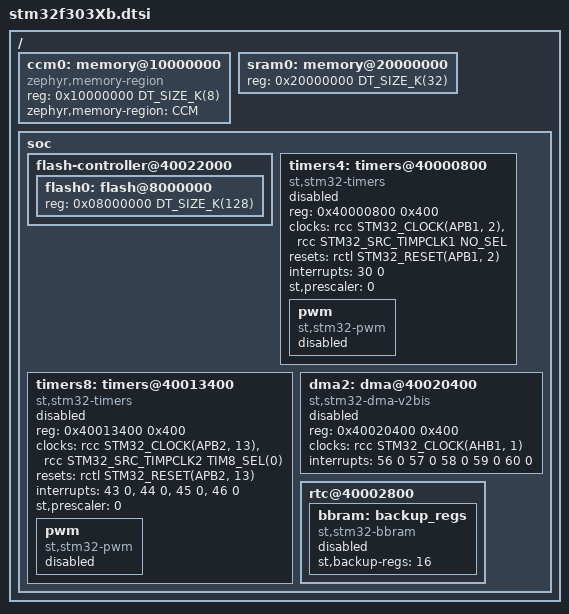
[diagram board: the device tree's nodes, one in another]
/*
 * Copyright (c) 2023 Martin Gritzan
 *
 * SPDX-License-Identifier: Apache-2.0
 */

#include <mem.h>
#include <st/f3/stm32f303.dtsi>

/ {
	ccm0: memory@10000000 {
		compatible = "zephyr,memory-region", "st,stm32-ccm";
		reg = <0x10000000 DT_SIZE_K(8)>;
		zephyr,memory-region = "CCM";
	};

	sram0: memory@20000000 {
		reg = <0x20000000 DT_SIZE_K(32)>;
	};

	soc {
		flash-controller@40022000 {
			flash0: flash@8000000 {
				reg = <0x08000000 DT_SIZE_K(128)>;
			};
		};

		timers4: timers@40000800 {
			compatible = "st,stm32-timers";
			reg = <0x40000800 0x400>;
			clocks = <&rcc STM32_CLOCK(APB1, 2)>,
				 <&rcc STM32_SRC_TIMPCLK1 NO_SEL>;
			resets = <&rctl STM32_RESET(APB1, 2)>;
			interrupts = <30 0>;
			interrupt-names = "global";
			st,prescaler = <0>;
			status = "disabled";

			pwm {
				compatible = "st,stm32-pwm";
				status = "disabled";
				#pwm-cells = <3>;
			};
		};

		timers8: timers@40013400 {
			compatible = "st,stm32-timers";
			reg = <0x40013400 0x400>;
			clocks = <&rcc STM32_CLOCK(APB2, 13)>,
				 <&rcc STM32_SRC_TIMPCLK2 TIM8_SEL(0)>;
			resets = <&rctl STM32_RESET(APB2, 13)>;
			interrupts = <43 0>, <44 0>, <45 0>, <46 0>;
			interrupt-names = "brk", "up", "trgcom", "cc";
			st,prescaler = <0>;
			status = "disabled";

			pwm {
				compatible = "st,stm32-pwm";
				status = "disabled";
				#pwm-cells = <3>;
			};
		};

		dma2: dma@40020400 {
			compatible = "st,stm32-dma-v2bis";
			#dma-cells = <2>;
			reg = <0x40020400 0x400>;
			clocks = <&rcc STM32_CLOCK(AHB1, 1)>;
			interrupts = <56 0 57 0 58 0 59 0 60 0>;
			status = "disabled";
		};

		rtc@40002800 {
			bbram: backup_regs {
				compatible = "st,stm32-bbram";
				st,backup-regs = <16>;
				status = "disabled";
			};
		};
	};
};
